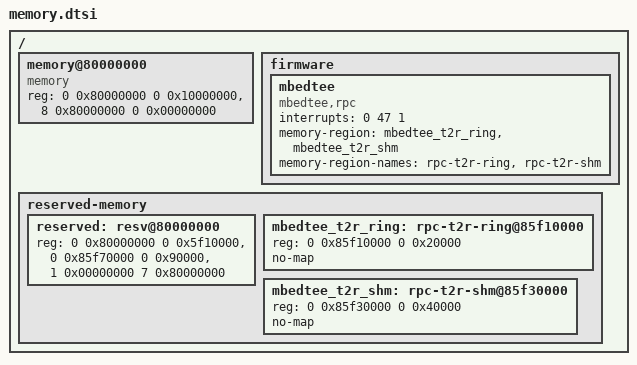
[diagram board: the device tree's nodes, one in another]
// SPDX-License-Identifier: Apache-2.0
/*
 * Copyright (c) 2019 Xing Loong <xing.xl.loong@gmail.com>
 */

/{
	#address-cells = <2>;
	#size-cells = <2>;

	memory@80000000 {
		compatible = "memory";
		device_type = "memory";

		reg = <0 0x80000000 0 0x10000000>,
			<8 0x80000000 0 0x00000000>;
	};

	firmware {
		mbedtee {
			compatible = "mbedtee,rpc";

			/* GIC SPI edge-rising for TEE->REE notification */
			interrupts = <0 47 1>;

			/* shared memory regions */
			memory-region = <&mbedtee_t2r_ring>, <&mbedtee_t2r_shm>;
			memory-region-names = "rpc-t2r-ring", "rpc-t2r-shm";
		};
	};

	reserved-memory {
		#address-cells = <2>;
		#size-cells = <2>;
		ranges;

		reserved: resv@80000000 {
			reg = <0 0x80000000 0 0x5f10000>,
				<0 0x85f70000 0 0x90000>,
				<1 0x00000000 7 0x80000000>;
		};

		mbedtee_t2r_ring: rpc-t2r-ring@85f10000 {
			reg = <0 0x85f10000 0 0x20000>;
			no-map;
		};

		mbedtee_t2r_shm: rpc-t2r-shm@85f30000 {
			reg = <0 0x85f30000 0 0x40000>;
			no-map;
		};
	};
};
